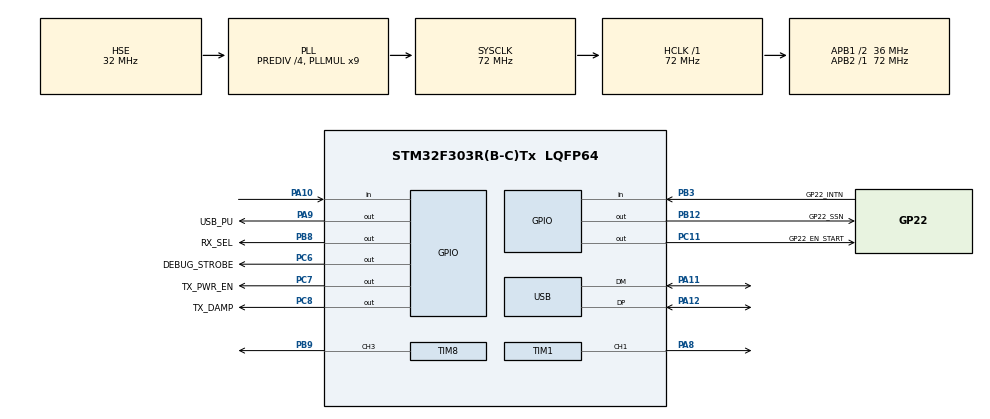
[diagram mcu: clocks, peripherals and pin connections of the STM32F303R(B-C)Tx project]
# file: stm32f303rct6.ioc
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Mcu.Family=STM32F3
Mcu.Name=STM32F303R(B-C)Tx
Mcu.Package=LQFP64
NVIC.PriorityGroup=NVIC_PRIORITYGROUP_4
NVIC.TIM6_DAC_IRQn=true\:0\:0\:false\:false\:true\:true\:true\:true
NVIC.USB_LP_CAN_RX0_IRQn=true\:5\:0\:false\:false\:true\:false\:true\:true
PA10.Signal=GPIO_Input
PA11.Mode=Device
PA11.Signal=USB_DM
PA12.Mode=Device
PA12.Signal=USB_DP
PA13.Mode=Serial_Wire
PA13.Signal=SYS_JTMS-SWDIO
PA14.Mode=Serial_Wire
PA14.Signal=SYS_JTCK-SWCLK
PA8.GPIO_Speed=GPIO_SPEED_FREQ_HIGH
PA8.Signal=S_TIM1_CH1
PA9.GPIO_Label=USB_PU
PA9.Signal=GPIO_Output
PB12.GPIO_Label=GP22_SSN
PB12.Signal=GPIO_Output
PB3.GPIO_Label=GP22_INTN
PB3.Signal=GPIO_Input
PB8.GPIO_Label=RX_SEL
PB8.Signal=GPIO_Output
PB9.GPIO_Speed=GPIO_SPEED_FREQ_HIGH
PB9.Signal=S_TIM8_CH3
PC11.GPIO_Label=GP22_EN_START
PC11.Signal=GPIO_Output
PC6.GPIO_Label=DEBUG_STROBE
PC6.Signal=GPIO_Output
PC7.GPIO_Label=TX_PWR_EN
PC7.Signal=GPIO_Output
PC8.GPIO_Label=TX_DAMP
PC8.Signal=GPIO_Output
PF0-OSC_IN.Mode=HSE-External-Oscillator
PF0-OSC_IN.Signal=RCC_OSC_IN
PF1-OSC_OUT.Mode=HSE-External-Oscillator
PF1-OSC_OUT.Signal=RCC_OSC_OUT
ProjectManager.HeapSize=0x800
ProjectManager.StackSize=0x800
ProjectManager.TargetToolchain=STM32CubeIDE
RCC.AHBFreq_Value=72000000
RCC.APB1CLKDivider=RCC_HCLK_DIV2
RCC.APB1Freq_Value=36000000
RCC.APB1TimFreq_Value=72000000
RCC.APB2Freq_Value=72000000
RCC.APB2TimFreq_Value=72000000
RCC.CortexFreq_Value=72000000
RCC.HCLKFreq_Value=72000000
RCC.HSE_VALUE=32000000
RCC.HSI_VALUE=8000000
RCC.LSE_VALUE=32768
RCC.PLLMUL=RCC_PLL_MUL9
RCC.PRESCALERUSB=RCC_USBCLKSOURCE_PLL_DIV1_5
RCC.RCC_PLLsource_Clock_Source_FROM_HSE=RCC_HSE_PREDIV_DIV4
RCC.SYSCLKFreq_VALUE=72000000
RCC.SYSCLKSourceVirtual=RCC_SYSCLKSOURCE_PLLCLK
RCC.TIM1Selection=RCC_TIM1CLK_PLLCLK
RCC.TIM8Selection=RCC_TIM8CLK_PLLCLK
RCC.USBFreq_Value=48000000
SH.S_TIM1_CH1.0=TIM1_CH1,PWM Generation1 CH1
SH.S_TIM8_CH3.0=TIM8_CH3,PWM Generation3 CH3
TIM1.AutoReloadPreload=TIM_AUTORELOAD_PRELOAD_ENABLE
TIM1.Channel-PWM\ Generation1\ CH1=TIM_CHANNEL_1
TIM1.OCMode_PWM-PWM\ Generation1\ CH1=TIM_OCMODE_PWM2
TIM1.Period=1999
TIM1.Pulse-PWM\ Generation1\ CH1=100
TIM1.TIM_MasterOutputTrigger=TIM_TRGO_ENABLE
TIM6.Period=999
TIM6.Prescaler=71
TIM8.AutoReloadPreload=TIM_AUTORELOAD_PRELOAD_ENABLE
TIM8.Channel-PWM\ Generation3\ CH3=TIM_CHANNEL_3
TIM8.OCMode_PWM-PWM\ Generation3\ CH3=TIM_OCMODE_PWM2
TIM8.Period=1999
TIM8.Pulse-PWM\ Generation3\ CH3=100
TIM8.SlaveMode=TIM_SLAVEMODE_TRIGGER
TIM8.TriggerSource=TIM_TS_ITR0
USB_DEVICE.CLASS_NAME_FS=CDC
USB_DEVICE.VirtualMode=Cdc
USB_DEVICE.VirtualModeFS=Cdc_FS
VP_TIM1_VS_ClockSourceINT.Mode=Internal
VP_TIM6_VS_ClockSourceINT.Mode=Enable_Timer
VP_TIM8_VS_ClockSourceINT.Mode=Internal
VP_USB_DEVICE_VS_USB_DEVICE_CDC_FS.Mode=CDC_FS
board=custom

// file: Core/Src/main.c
/* USER CODE BEGIN Header */
/**
  ******************************************************************************
  * @file           : main.c
  * @brief          : Main program body
  ******************************************************************************
  * @attention
  *
  * Copyright (c) 2026 STMicroelectronics.
  * All rights reserved.
  *
  * This software is licensed under terms that can be found in the LICENSE file
  * in the root directory of this software component.
  * If no LICENSE file comes with this software, it is provided AS-IS.
  *
  ******************************************************************************
  */
/* USER CODE END Header */
#include "main.h"
#include "tim.h"
#include "usb_device.h"
#include "gpio.h"

/* USER CODE BEGIN Includes */
#include "../User/app/appMain.h"
/* USER CODE END Includes */

void SystemClock_Config(void);

int main(void)
{

  /* MCU Configuration--------------------------------------------------------*/

  /* Reset of all peripherals, Initializes the Flash interface and the Systick. */
  HAL_Init();

  /* Configure the system clock */
  SystemClock_Config();

  /* Initialize all configured peripherals */
  MX_GPIO_Init();
  MX_TIM1_Init();
  MX_TIM6_Init();
  MX_TIM8_Init();
  MX_USB_DEVICE_Init();
  /* USER CODE BEGIN 2 */
  /* PA9 drives the 1.5K D+ pull-up: high attaches the device to the USB host */
  HAL_GPIO_WritePin(USB_PU_GPIO_Port, USB_PU_Pin, GPIO_PIN_SET);
  TIM2_PrfTrigger_Init();
  appMain();
  /* USER CODE END 2 */

  /* Infinite loop */
  while (1)
  {

  }
}

void SystemClock_Config(void)
{
  RCC_OscInitTypeDef RCC_OscInitStruct = {0};
  RCC_ClkInitTypeDef RCC_ClkInitStruct = {0};
  RCC_PeriphCLKInitTypeDef PeriphClkInit = {0};

  /** Initializes the RCC Oscillators according to the specified parameters
  * in the RCC_OscInitTypeDef structure.
  */
  RCC_OscInitStruct.OscillatorType = RCC_OSCILLATORTYPE_HSE;
  RCC_OscInitStruct.HSEState = RCC_HSE_ON;
  RCC_OscInitStruct.HSEPredivValue = RCC_HSE_PREDIV_DIV4;
  RCC_OscInitStruct.HSIState = RCC_HSI_ON;
  RCC_OscInitStruct.PLL.PLLState = RCC_PLL_ON;
  RCC_OscInitStruct.PLL.PLLSource = RCC_PLLSOURCE_HSE;
  RCC_OscInitStruct.PLL.PLLMUL = RCC_PLL_MUL9;
  if (HAL_RCC_OscConfig(&RCC_OscInitStruct) != HAL_OK)
  {
    Error_Handler();
  }

  /** Initializes the CPU, AHB and APB buses clocks
  */
  RCC_ClkInitStruct.ClockType = RCC_CLOCKTYPE_HCLK|RCC_CLOCKTYPE_SYSCLK
                              |RCC_CLOCKTYPE_PCLK1|RCC_CLOCKTYPE_PCLK2;
  RCC_ClkInitStruct.SYSCLKSource = RCC_SYSCLKSOURCE_PLLCLK;
  RCC_ClkInitStruct.AHBCLKDivider = RCC_SYSCLK_DIV1;
  RCC_ClkInitStruct.APB1CLKDivider = RCC_HCLK_DIV2;
  RCC_ClkInitStruct.APB2CLKDivider = RCC_HCLK_DIV1;

  if (HAL_RCC_ClockConfig(&RCC_ClkInitStruct, FLASH_LATENCY_2) != HAL_OK)
  {
    Error_Handler();
  }
  PeriphClkInit.PeriphClockSelection = RCC_PERIPHCLK_USB|RCC_PERIPHCLK_TIM1
                              |RCC_PERIPHCLK_TIM8;
  PeriphClkInit.USBClockSelection = RCC_USBCLKSOURCE_PLL_DIV1_5;
  PeriphClkInit.Tim1ClockSelection = RCC_TIM1CLK_PLLCLK;
  PeriphClkInit.Tim8ClockSelection = RCC_TIM8CLK_PLLCLK;
  if (HAL_RCCEx_PeriphCLKConfig(&PeriphClkInit) != HAL_OK)
  {
    Error_Handler();
  }
}

void Error_Handler(void)
{
  __disable_irq();
  while (1)
  {
  }
}
